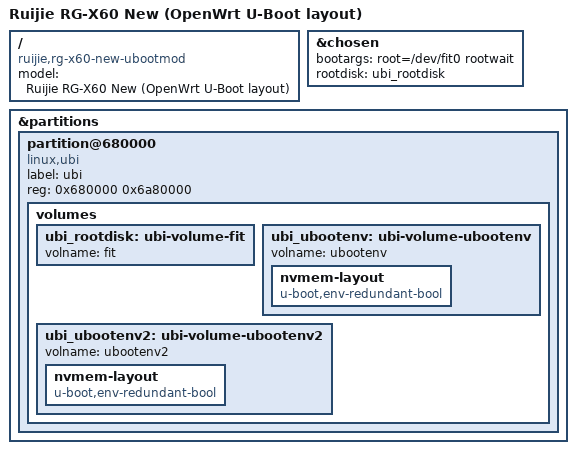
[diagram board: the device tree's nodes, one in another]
// SPDX-License-Identifier: (GPL-2.0 OR MIT)

/dts-v1/;
#include "mt7986a-ruijie-rg-x60-new-common.dtsi"

/ {
	compatible = "ruijie,rg-x60-new-ubootmod", "mediatek,mt7986a";
	model = "Ruijie RG-X60 New (OpenWrt U-Boot layout)";
};

&chosen {
	bootargs = "root=/dev/fit0 rootwait";
	rootdisk = <&ubi_rootdisk>;
};

&partitions {
	partition@680000 {
		compatible = "linux,ubi";
		label = "ubi";
		reg = <0x680000 0x6a80000>;

		volumes {
			ubi_rootdisk: ubi-volume-fit {
				volname = "fit";
			};

			ubi_ubootenv: ubi-volume-ubootenv {
				volname = "ubootenv";
			};

			ubi_ubootenv2: ubi-volume-ubootenv2 {
				volname = "ubootenv2";
			};
		};
	};
};

&ubi_ubootenv {
	nvmem-layout {
		compatible = "u-boot,env-redundant-bool";
	};
};

&ubi_ubootenv2 {
	nvmem-layout {
		compatible = "u-boot,env-redundant-bool";
	};
};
